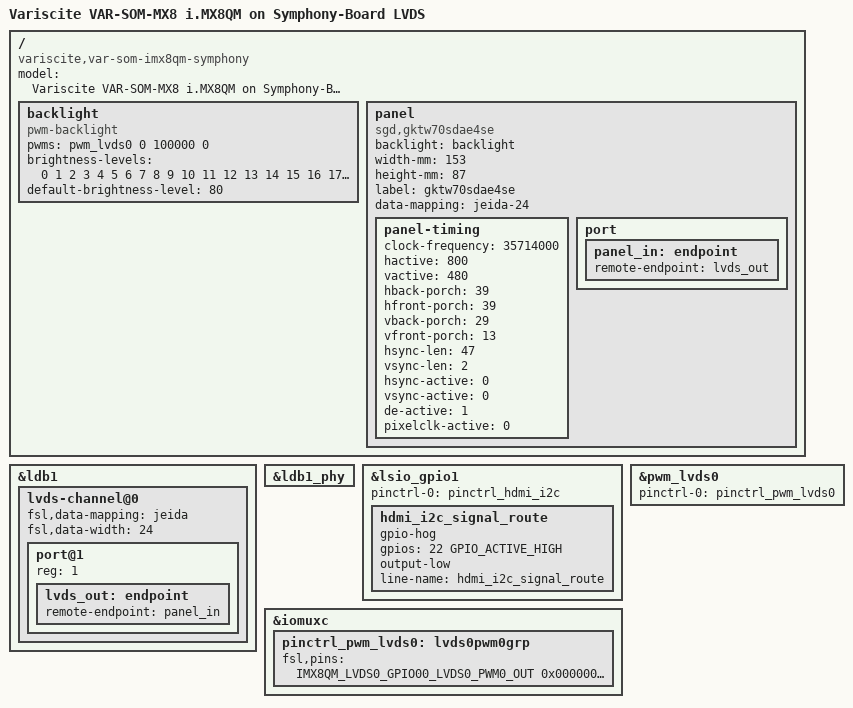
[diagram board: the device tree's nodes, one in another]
// SPDX-License-Identifier: (GPL-2.0+ OR MIT)
/*       
 * Copyright (C) 2026 Variscite Ltd. - https://www.variscite.com/
 *
 */

#include "imx8qm-var-som-symphony.dts"

/ {
	model = "Variscite VAR-SOM-MX8 i.MX8QM on Symphony-Board LVDS";
	compatible = "variscite,var-som-imx8qm-symphony",
		     "variscite,var-som-imx8qm", "fsl,imx8qm";

       backlight: backlight {
		compatible = "pwm-backlight";
		pwms = <&pwm_lvds0 0 100000 0>;
		brightness-levels = <0  1  2  3  4  5  6  7  8  9
							 10 11 12 13 14 15 16 17 18 19
							 20 21 22 23 24 25 26 27 28 29
							 30 31 32 33 34 35 36 37 38 39
							 40 41 42 43 44 45 46 47 48 49
							 50 51 52 53 54 55 56 57 58 59
							 60 61 62 63 64 65 66 67 68 69
							 70 71 72 73 74 75 76 77 78 79
							 80 81 82 83 84 85 86 87 88 89
							 90 91 92 93 94 95 96 97 98 99
							 100>;
		default-brightness-level = <80>;
		status = "okay";
	};

	panel {
		compatible = "sgd,gktw70sdae4se", "panel-lvds";
		backlight = <&backlight>;
		width-mm = <153>;
		height-mm = <87>;
		label = "gktw70sdae4se";
		data-mapping = "jeida-24";
		status = "okay";

		panel-timing {
			clock-frequency = <35714000>;
			hactive = <800>;
			vactive = <480>;
			hback-porch = <39>;
			hfront-porch = <39>;
			vback-porch = <29>;
			vfront-porch = <13>;
			hsync-len = <47>;
			vsync-len = <2>;
			hsync-active = <0>;
			vsync-active = <0>;
			de-active = <1>;
			pixelclk-active = <0>;
		};

		port {
			panel_in: endpoint {
				remote-endpoint = <&lvds_out>;
			};
		};
	};
};



&ldb1 {
	status = "okay";

	lvds-channel@0 {
		fsl,data-mapping = "jeida";
		fsl,data-width = <24>;
		status = "okay";

		port@1 {
			reg = <1>;

			lvds_out: endpoint {
				remote-endpoint = <&panel_in>;
			};
		};
	};
};

&ldb1_phy {
	status = "okay";
};

&lsio_gpio1 {
	pinctrl-names = "default";
	pinctrl-0 = <&pinctrl_hdmi_i2c>;

	hdmi_i2c_signal_route {
		gpio-hog;
		gpios = <22 GPIO_ACTIVE_HIGH>;
		output-low;
		line-name = "hdmi_i2c_signal_route";
	};
};

&pwm_lvds0 {
	pinctrl-names = "default";
	pinctrl-0 = <&pinctrl_pwm_lvds0>;
	status = "okay";
};

&iomuxc {
	pinctrl_pwm_lvds0: lvds0pwm0grp {
		fsl,pins = <
			IMX8QM_LVDS0_GPIO00_LVDS0_PWM0_OUT	0x00000020
		>;
	};
};
